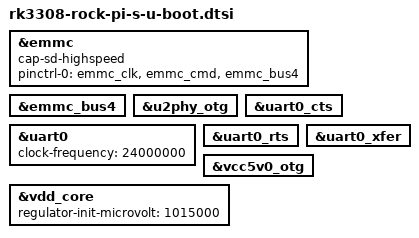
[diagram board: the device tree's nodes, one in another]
// SPDX-License-Identifier: GPL-2.0+
/*
 * (C) Copyright 2018-2019 Rockchip Electronics Co., Ltd
 */
#include "rk3308-u-boot.dtsi"

&emmc {
	cap-sd-highspeed;
	pinctrl-names = "default";
	pinctrl-0 = <&emmc_clk &emmc_cmd &emmc_bus4>;
};

&emmc_bus4 {
	bootph-pre-ram;
	bootph-some-ram;
};

&u2phy_otg {
	/delete-property/ phy-supply;
};

&uart0 {
	bootph-all;
	clock-frequency = <24000000>;
};

&uart0_cts {
	bootph-pre-sram;
	bootph-pre-ram;
};

&uart0_rts {
	bootph-pre-sram;
	bootph-pre-ram;
};

&uart0_xfer {
	bootph-pre-sram;
	bootph-pre-ram;
};

&vcc5v0_otg {
	/delete-property/ regulator-always-on;
};

&vdd_core {
	regulator-init-microvolt = <1015000>;
};
